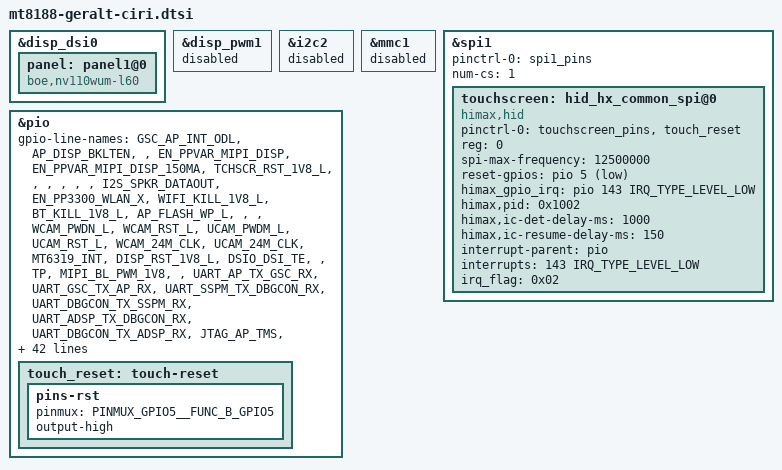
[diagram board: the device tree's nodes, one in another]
// SPDX-License-Identifier: (GPL-2.0 OR MIT)
/*
 * Copyright 2023 Google LLC
 */
/dts-v1/;
#include "mt8188-geralt.dtsi"

/delete-node/ &dp_intf0;
/delete-node/ &edp_tx;
/delete-node/ &panel;
/delete-node/ &backlight_lcd0;
/delete-node/ &pp3300_dx_edp;

&disp_dsi0 {
	panel: panel1@0 {
		compatible = "boe,nv110wum-l60";
	};
};

&disp_pwm1 {
	status = "disabled";
};

&i2c2 {
	status = "disabled";
};

&mmc1 {
	status = "disabled";
};

&spi1 {
	pinctrl-names = "default";
	pinctrl-0 = <&spi1_pins>;
	status = "okay";
	dma-names = "tx","rx";
	num-cs = <1>;
	#address-cells = <1>;
	#size-cells = <0>;

	touchscreen: hid_hx_common_spi@0 {
		compatible = "himax,hid";
		pinctrl-names = "default";
		pinctrl-0 = <&touchscreen_pins &touch_reset>;
		reg = <0>;
		spi-max-frequency = <12500000>;
		status = "okay";
		reset-gpios = <&pio 5  GPIO_ACTIVE_LOW>;
		himax_gpio_irq = <&pio 143  IRQ_TYPE_LEVEL_LOW>;
		himax,pid = <0x1002>;
		himax,ic-det-delay-ms = <1000>;
		himax,ic-resume-delay-ms = <150>;

		interrupt-parent = <&pio>;
		interrupts = <143 IRQ_TYPE_LEVEL_LOW>;
		irq_flag = <0x02>;
	};
};

&pio {
	pinctrl-names = "default";

	gpio-line-names =
		"GSC_AP_INT_ODL",
		"AP_DISP_BKLTEN",
		"",
		"EN_PPVAR_MIPI_DISP",
		"EN_PPVAR_MIPI_DISP_150MA",
		"TCHSCR_RST_1V8_L",
		"",
		"",
		"",
		"",
		"",
		"I2S_SPKR_DATAOUT",
		"EN_PP3300_WLAN_X",
		"WIFI_KILL_1V8_L",
		"BT_KILL_1V8_L",
		"AP_FLASH_WP_L",
		"",
		"",
		"WCAM_PWDN_L",
		"WCAM_RST_L",
		"UCAM_PWDM_L",
		"UCAM_RST_L",
		"WCAM_24M_CLK",
		"UCAM_24M_CLK",
		"MT6319_INT",
		"DISP_RST_1V8_L",
		"DSIO_DSI_TE",
		"",
		"TP",
		"MIPI_BL_PWM_1V8",
		"",
		"UART_AP_TX_GSC_RX",
		"UART_GSC_TX_AP_RX",
		"UART_SSPM_TX_DBGCON_RX",
		"UART_DBGCON_TX_SSPM_RX",
		"UART_ADSP_TX_DBGCON_RX",
		"UART_DBGCON_TX_ADSP_RX",
		"JTAG_AP_TMS",
		"JTAG_AP_TCK",
		"JTAG_AP_TDI",
		"JTAG_AP_TDO",
		"JTAG_AP_TRST",
		"AP_KPCOL0",
		"TP",
		"",
		"TP",
		"EC_AP_HPD_OD",
		"PCIE_WAKE_1V8_ODL",
		"PCIE_RST_1V8_L",
		"PCIE_CLKREQ_1V8_ODL",
		"NC",
		"NC",
		"",
		"",
		"",
		"AP_I2C_AUD_SCL_1V8",
		"AP_I2C_AUD_SDA_1V8",
		"AP_I2C_TPM_SCL_1V8",
		"AP_I2C_TPM_SDA_1V8",
		"AP_I2C_TCHSCR_SCL_1V8",
		"AP_I2C_TCHSCR_SDA_1V8",
		"AP_I2C_PMIC_SAR_SCL_1V8",
		"AP_I2C_PMIC_SAR_SDA_1V8",
		"AP_I2C_EC_HID_KB_SCL_1V8",
		"AP_I2C_EC_HID_KB_SDA_1V8",
		"AP_I2C_UCAM_SCL_1V8",
		"AP_I2C_UCAM_SDA_1V8",
		"AP_I2C_WCAM_SCL_1V8",
		"AP_I2C_WCAM_SDA_1V8",
		"SPI_AP_CS_EC_L",
		"SPI_AP_CLK_EC",
		"SPI_AP_DO_EC_DI",
		"SPI_AP_DI_EC_DO",
		"TP",
		"TP",
		"SPI_AP_CS_TCHSCR_L",
		"SPI_AP_CLK_TCHSCR",
		"SPI_AP_DO_TCHSCR_DI",
		"SPI_AP_DI_TCHSCR_DO",
		"TP",
		"TP",
		"TP",
		"TP",
		"",
		"",
		"",
		"TP",
		"",
		"",
		"",
		"",
		"",
		"PWRAP_SPI_CS_L",
		"PWRAP_SPI_CK",
		"PWRAP_SPI_MOSI",
		"PWRAP_SPI_MISO",
		"SRCLKENA0",
		"SRCLKENA1",
		"SCP_VREQ_VAO",
		"AP_RTC_CLK32K",
		"AP_PMIC_WDTRST_L",
		"AUD_CLK_MOSI",
		"AUD_SYNC_MOSI",
		"AUD_DAT_MOSI0",
		"AUD_DAT_MOSI1",
		"AUD_DAT_MISO0",
		"AUD_DAT_MISO1",
		"",
		"HP_INT_ODL",
		"SPKR_INT_ODL",
		"I2S_HP_DATAIN",
		"",
		"I2S_SPKR_MCLK",
		"I2S_SPKR_BCLK",
		"I2S_HP_MCLK",
		"I2S_HP_BCLK",
		"I2S_HP_LRCK",
		"I2S_HP_DATAOUT",
		"RST_SPKR_L",
		"I2S_SPKR_LRCK",
		"I2S_SPKR_DATAIN",
		"",
		"",
		"",
		"",
		"SPI_AP_CLK_ROM",
		"SPI_AP_CS_ROM_L",
		"SPI_AP_DO_ROM_DI",
		"SPI_AP_DI_ROM_DO",
		"TP",
		"TP",
		"",
		"",
		"",
		"",
		"",
		"",
		"",
		"",
		"EN_PP2800A_UCAM_X",
		"EN_PP1200_UCAM_X",
		"EN_PP2800A_WCAM_X",
		"EN_PP1100_WCAM_X",
		"TCHSCR_INI_1V8_L",
		"",
		"MT7921_PMU_EN_1V8",
		"",
		"AP_EC_WARM_RST_REQ",
		"EC_AP_HID_INT_ODL",
		"EC_AP_INT_ODL",
		"AP_XHCI_INIT_DONE",
		"EMMC_DAT7",
		"EMMC_DAT6",
		"EMMC_DAT5",
		"EMMC_DAT4",
		"EMMC_RST_L",
		"EMMC_CMD",
		"EMMC_CLK",
		"EMMC_DAT3",
		"EMMC_DAT2",
		"EMMC_DAT1",
		"EMMC_DAT0",
		"EMMC_STRB",
		"",
		"",
		"",
		"",
		"",
		"",
		"",
		"",
		"USB3_HUB_RST_L",
		"EC_AP_RSVD0_ODL",
		"",
		"",
		"SPMI_SCL",
		"SPMI_SDA";

	touch_reset: touch-reset {
		pins-rst {
			pinmux = <PINMUX_GPIO5__FUNC_B_GPIO5>;
			output-high;
		};
	};
};
